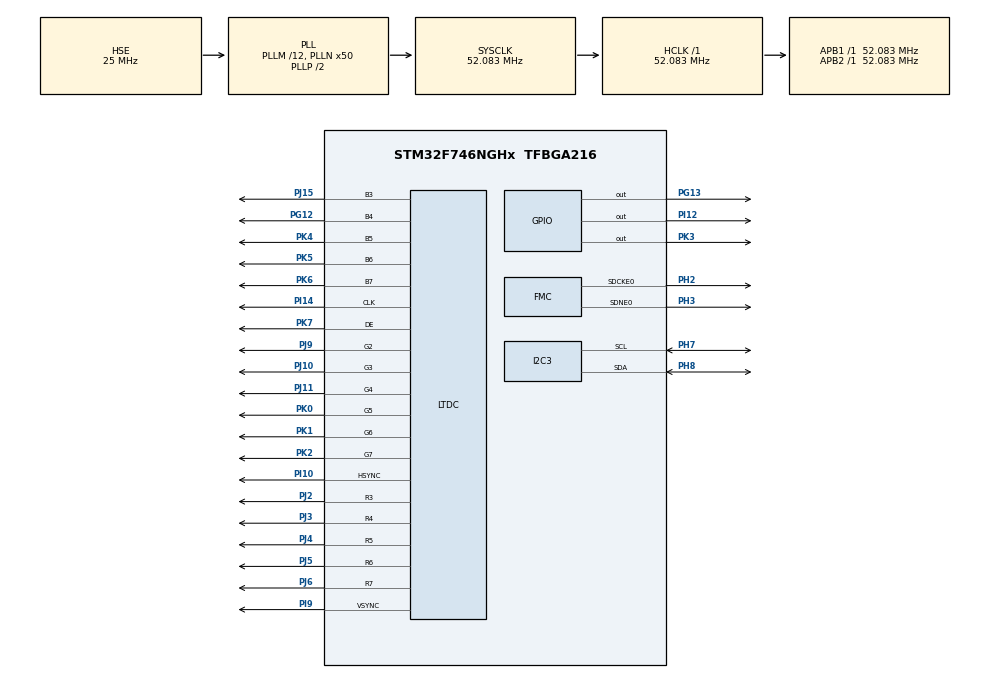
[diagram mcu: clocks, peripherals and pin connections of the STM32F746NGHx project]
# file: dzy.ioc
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GRAPHICS.BSP.number=1
GRAPHICS.Check_OTM8009A_PixelFormat-STemWin=1
GRAPHICS.DMA2D_Graphics-STemWin=0
GRAPHICS.EA_1_Apptype=Window
GRAPHICS.EA_1_executable_name-STemWin=GUIBuilder.exe
GRAPHICS.GUI_NUM_LAYERS-STemWin=1
GRAPHICS.GUI_Num_KBYTES=10
GRAPHICS.LIN_Color_Conversion_Layer0=GUICC_M565
GRAPHICS.LIN_Frame_Buffer_Depth_Layer0-STemWin=16
GRAPHICS.OPTIM_OS_use-STemWin=4
GRAPHICS.USE_Embedded_Wizard-STemWin=0
GRAPHICS.USE_STTouchGFX-STemWin=0
GRAPHICS.UseGUIBuilder=Enabled
GRAPHICS.Use_SDRAM-STemWin=SDRAM1_BANK1
GRAPHICS0.BSP.STBoard=false
GRAPHICS0.BSP.api=Unknown
GRAPHICS0.BSP.i2caddr=0
GRAPHICS0.BSP.instance=PG13
GRAPHICS0.BSP.ip=GPIO
GRAPHICS0.BSP.mode=Output
GRAPHICS0.BSP.name=LCD Reset Pin XRES
GRAPHICS0.BSP.solution=PG13
I2C3.Timing=0x00D0FFFF
LTDC.ActiveH=272
LTDC.ActiveW=480
LTDC.Alpha_L0=255
LTDC.FBStartAdress_L0=0x20010400
LTDC.HBP=43
LTDC.HFP=8
LTDC.HSync=1
LTDC.ImageHeight_L0=272
LTDC.ImageWidth_L0=480
LTDC.Layers=0
LTDC.PixelFormat_L0=LTDC_PIXEL_FORMAT_RGB565
LTDC.VBP=12
LTDC.VFP=4
LTDC.VSync=10
LTDC.WindowX1_L0=480
LTDC.WindowY1_L0=272
Mcu.Family=STM32F7
Mcu.Name=STM32F746NGHx
Mcu.Package=TFBGA216
NVIC.PriorityGroup=NVIC_PRIORITYGROUP_4
PA13.Mode=Trace_Asynchronous_SW
PA13.Signal=SYS_JTMS-SWDIO
PA14.Mode=Trace_Asynchronous_SW
PA14.Signal=SYS_JTCK-SWCLK
PB3.Mode=Trace_Asynchronous_SW
PB3.Signal=SYS_JTDO-SWO
PG12.Mode=RGB565
PG12.Signal=LTDC_B4
PG13.Signal=GPIO_Output
PH0/OSC_IN.Mode=HSE-External-Oscillator
PH0/OSC_IN.Signal=RCC_OSC_IN
PH1/OSC_OUT.Mode=HSE-External-Oscillator
PH1/OSC_OUT.Signal=RCC_OSC_OUT
PH2.Mode=SdramChipSelect1_1
PH2.Signal=FMC_SDCKE0
PH3.Mode=SdramChipSelect1_1
PH3.Signal=FMC_SDNE0
PH7.Mode=I2C
PH7.Signal=I2C3_SCL
PH8.Mode=I2C
PH8.Signal=I2C3_SDA
PI10.Mode=RGB565
PI10.Signal=LTDC_HSYNC
PI12.PinState=GPIO_PIN_SET
PI12.Signal=GPIO_Output
PI14.Mode=RGB565
PI14.Signal=LTDC_CLK
PI9.Mode=RGB565
PI9.Signal=LTDC_VSYNC
PJ10.Mode=RGB565
PJ10.Signal=LTDC_G3
PJ11.Mode=RGB565
PJ11.Signal=LTDC_G4
PJ15.Mode=RGB565
PJ15.Signal=LTDC_B3
PJ2.Mode=RGB565
PJ2.Signal=LTDC_R3
PJ3.Mode=RGB565
PJ3.Signal=LTDC_R4
PJ4.Mode=RGB565
PJ4.Signal=LTDC_R5
PJ5.Mode=RGB565
PJ5.Signal=LTDC_R6
PJ6.Mode=RGB565
PJ6.Signal=LTDC_R7
PJ9.Mode=RGB565
PJ9.Signal=LTDC_G2
PK0.Mode=RGB565
PK0.Signal=LTDC_G5
PK1.Mode=RGB565
PK1.Signal=LTDC_G6
PK2.Mode=RGB565
PK2.Signal=LTDC_G7
PK3.PinState=GPIO_PIN_SET
PK3.Signal=GPIO_Output
PK4.Mode=RGB565
PK4.Signal=LTDC_B5
PK5.Mode=RGB565
PK5.Signal=LTDC_B6
PK6.Mode=RGB565
PK6.Signal=LTDC_B7
PK7.Mode=RGB565
PK7.Signal=LTDC_DE
ProjectManager.HeapSize=0x1000
ProjectManager.StackSize=0x1000
ProjectManager.TargetToolchain=EWARM V8
RCC.AHBFreq_Value=52083333.33333333
RCC.APB1Freq_Value=52083333.33333333
RCC.APB1TimFreq_Value=52083333.33333333
RCC.APB2Freq_Value=52083333.33333333
RCC.APB2TimFreq_Value=52083333.33333333
RCC.CortexFreq_Value=52083333.33333333
RCC.HCLKFreq_Value=52083333.33333333
RCC.HSE_VALUE=25000000
RCC.HSI_VALUE=16000000
RCC.LSE_VALUE=32768
RCC.PLLM=12
RCC.PLLN=50
RCC.PLLSAIN=96
RCC.PLLSAIR=5
RCC.PLLSAIRDiv=RCC_PLLSAIDIVR_4
RCC.PLLSourceVirtual=RCC_PLLSOURCE_HSE
RCC.SYSCLKFreq_VALUE=52083333.33333333
RCC.SYSCLKSource=RCC_SYSCLKSOURCE_PLLCLK
RCC.USBFreq_Value=52083333.33333333
RCC.VCOOutputFreq_Value=104166666.66666666
RTC.Format=RTC_FORMAT_BIN
VP_CRC_VS_CRC.Mode=CRC_Activate
VP_GRAPHICS_VS-DisplayInterface-LTDC.Mode=Display Parallel Interface using LTDC
VP_GRAPHICS_VS-STemWin.Mode=STemWin
VP_RTC_VS_RTC_Activate.Mode=RTC_Enabled
VP_RTC_VS_RTC_Calendar.Mode=RTC_Calendar
board=custom

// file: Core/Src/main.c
/* USER CODE BEGIN Header */
/**
  ******************************************************************************
  * @file           : main.c
  * @brief          : Main program body
  ******************************************************************************
  * @attention
  *
  * <h2><center>&copy; Copyright (c) 2020 STMicroelectronics.
  * All rights reserved.</center></h2>
  *
  * This software component is licensed by ST under Ultimate Liberty license
  * SLA0044, the "License"; You may not use this file except in compliance with
  * the License. You may obtain a copy of the License at:
  *                             www.st.com/SLA0044
  *
  ******************************************************************************
  */
/* USER CODE END Header */

#include "main.h"

/* USER CODE BEGIN Includes */

/*2020.10.26改动说明--孙天一
STM32CubeMax：
  工程重建，配置了工程文件选项：主要包括基础配置以及RTC、FMC、I2C3和LTDC以及GRAPHICS
IAR:
  因程序走入死循环且诊断不出问题所在，重新开始工程和程序编写。

*/

#include <stdio.h>

/* USER CODE END Includes */

CRC_HandleTypeDef hcrc;

I2C_HandleTypeDef hi2c3;

RTC_HandleTypeDef hrtc;

void SystemClock_Config(void);
static void MX_GPIO_Init(void);
static void MX_I2C3_Init(void);
static void MX_RTC_Init(void);
static void MX_CRC_Init(void);
extern void GRAPHICS_HW_Init(void);
extern void GRAPHICS_Init(void);
extern void GRAPHICS_MainTask(void);
/* USER CODE BEGIN PFP */
  RTC_TimeTypeDef sTime;//定义时间结构体
  RTC_DateTypeDef sDate;

/* USER CODE END PFP */

/* USER CODE BEGIN 0 */
void checkTouch(void)
{
    uint8_t buf[6];
    HAL_I2C_Mem_Read(&hi2c3, 0x70, 0x02, 1, buf, 1, 1000);
    //printf("Touch: %d point\n", buf[0]);

    if(buf[0] > 0 && buf[0] < 6)
    {
        HAL_I2C_Mem_Read(&hi2c3, 0x70, 0x03, 1, buf, 4, 1000);
        //printf("y: %d\n", (buf[0]<<8 | buf[1]) & 0x0fff);
        //printf("x: %d\n", (buf[2]<<8 | buf[3]) & 0x0fff);
        GUI_TOUCH_StoreState((buf[2]<<8 | buf[3]) & 0x0fff, (buf[0]<<8 | buf[1]) & 0x0fff);
    }
    else
    {
        GUI_TOUCH_StoreState(-1, -1);
    }
}
/* USER CODE END 0 */

int main(void)
{

  /* MCU Configuration--------------------------------------------------------*/

  /* Reset of all peripherals, Initializes the Flash interface and the Systick. */
  HAL_Init();

  /* Configure the system clock */
  SystemClock_Config();

  /* Initialize all configured peripherals */
  MX_GPIO_Init();
  MX_I2C3_Init();
  MX_RTC_Init();
  MX_CRC_Init();
  /* USER CODE BEGIN 2 */

//    while(1)
//{
//      GUI_Delay(900);
//      HAL_RTC_GetTime(&hrtc, &sTime, RTC_FORMAT_BIN);//得到时间和时期
//      HAL_RTC_GetDate(&hrtc, &sDate, RTC_FORMAT_BIN);
//      HAL_RTCEx_BKUPWrite(&hrtc,RTC_BKP_DR0,0x32F2);
//      printf("%02d/%02d/%02d\r\n",2000 + sDate.Year, sDate.Month, sDate.Date);
//      printf("%02d:%02d:%02d\r\n",sTime.Hours, sTime.Minutes, sTime.Seconds);
//}

  /* USER CODE END 2 */

/* Initialise the graphical hardware */
  GRAPHICS_HW_Init();

  /* Initialise the graphical stack engine */
  GRAPHICS_Init();

  /* Graphic application */
  GRAPHICS_MainTask();

  /* Infinite loop */
  for(;;);
}

void SystemClock_Config(void)
{
  RCC_OscInitTypeDef RCC_OscInitStruct = {0};
  RCC_ClkInitTypeDef RCC_ClkInitStruct = {0};
  RCC_PeriphCLKInitTypeDef PeriphClkInitStruct = {0};

  /** Configure the main internal regulator output voltage
  */
  __HAL_RCC_PWR_CLK_ENABLE();
  __HAL_PWR_VOLTAGESCALING_CONFIG(PWR_REGULATOR_VOLTAGE_SCALE3);
  /** Initializes the CPU, AHB and APB busses clocks
  */
  RCC_OscInitStruct.OscillatorType = RCC_OSCILLATORTYPE_LSI|RCC_OSCILLATORTYPE_HSE;
  RCC_OscInitStruct.HSEState = RCC_HSE_ON;
  RCC_OscInitStruct.LSIState = RCC_LSI_ON;
  RCC_OscInitStruct.PLL.PLLState = RCC_PLL_ON;
  RCC_OscInitStruct.PLL.PLLSource = RCC_PLLSOURCE_HSE;
  RCC_OscInitStruct.PLL.PLLM = 12;
  RCC_OscInitStruct.PLL.PLLN = 50;
  RCC_OscInitStruct.PLL.PLLP = RCC_PLLP_DIV2;
  RCC_OscInitStruct.PLL.PLLQ = 2;
  if (HAL_RCC_OscConfig(&RCC_OscInitStruct) != HAL_OK)
  {
    Error_Handler();
  }
  /** Activate the Over-Drive mode
  */
  if (HAL_PWREx_EnableOverDrive() != HAL_OK)
  {
    Error_Handler();
  }
  /** Initializes the CPU, AHB and APB busses clocks
  */
  RCC_ClkInitStruct.ClockType = RCC_CLOCKTYPE_HCLK|RCC_CLOCKTYPE_SYSCLK
                              |RCC_CLOCKTYPE_PCLK1|RCC_CLOCKTYPE_PCLK2;
  RCC_ClkInitStruct.SYSCLKSource = RCC_SYSCLKSOURCE_PLLCLK;
  RCC_ClkInitStruct.AHBCLKDivider = RCC_SYSCLK_DIV1;
  RCC_ClkInitStruct.APB1CLKDivider = RCC_HCLK_DIV1;
  RCC_ClkInitStruct.APB2CLKDivider = RCC_HCLK_DIV1;

  if (HAL_RCC_ClockConfig(&RCC_ClkInitStruct, FLASH_LATENCY_1) != HAL_OK)
  {
    Error_Handler();
  }
  PeriphClkInitStruct.PeriphClockSelection = RCC_PERIPHCLK_LTDC|RCC_PERIPHCLK_RTC
                              |RCC_PERIPHCLK_I2C3;
  PeriphClkInitStruct.PLLSAI.PLLSAIN = 96;
  PeriphClkInitStruct.PLLSAI.PLLSAIR = 5;
  PeriphClkInitStruct.PLLSAI.PLLSAIQ = 2;
  PeriphClkInitStruct.PLLSAI.PLLSAIP = RCC_PLLSAIP_DIV2;
  PeriphClkInitStruct.PLLSAIDivQ = 1;
  PeriphClkInitStruct.PLLSAIDivR = RCC_PLLSAIDIVR_4;
  PeriphClkInitStruct.RTCClockSelection = RCC_RTCCLKSOURCE_LSI;
  PeriphClkInitStruct.I2c3ClockSelection = RCC_I2C3CLKSOURCE_PCLK1;
  if (HAL_RCCEx_PeriphCLKConfig(&PeriphClkInitStruct) != HAL_OK)
  {
    Error_Handler();
  }
}

static void MX_CRC_Init(void)
{

  hcrc.Instance = CRC;
  hcrc.Init.DefaultPolynomialUse = DEFAULT_POLYNOMIAL_ENABLE;
  hcrc.Init.DefaultInitValueUse = DEFAULT_INIT_VALUE_ENABLE;
  hcrc.Init.InputDataInversionMode = CRC_INPUTDATA_INVERSION_NONE;
  hcrc.Init.OutputDataInversionMode = CRC_OUTPUTDATA_INVERSION_DISABLE;
  hcrc.InputDataFormat = CRC_INPUTDATA_FORMAT_BYTES;
  if (HAL_CRC_Init(&hcrc) != HAL_OK)
  {
    Error_Handler();
  }

}

static void MX_I2C3_Init(void)
{

  hi2c3.Instance = I2C3;
  hi2c3.Init.Timing = 0x00D0FFFF;
  hi2c3.Init.OwnAddress1 = 0;
  hi2c3.Init.AddressingMode = I2C_ADDRESSINGMODE_7BIT;
  hi2c3.Init.DualAddressMode = I2C_DUALADDRESS_DISABLE;
  hi2c3.Init.OwnAddress2 = 0;
  hi2c3.Init.OwnAddress2Masks = I2C_OA2_NOMASK;
  hi2c3.Init.GeneralCallMode = I2C_GENERALCALL_DISABLE;
  hi2c3.Init.NoStretchMode = I2C_NOSTRETCH_DISABLE;
  if (HAL_I2C_Init(&hi2c3) != HAL_OK)
  {
    Error_Handler();
  }
  /** Configure Analogue filter
  */
  if (HAL_I2CEx_ConfigAnalogFilter(&hi2c3, I2C_ANALOGFILTER_ENABLE) != HAL_OK)
  {
    Error_Handler();
  }
  /** Configure Digital filter
  */
  if (HAL_I2CEx_ConfigDigitalFilter(&hi2c3, 0) != HAL_OK)
  {
    Error_Handler();
  }

}

static void MX_RTC_Init(void)
{

  /* USER CODE BEGIN RTC_Init 0 */
 //RTC参数设置

  /* USER CODE END RTC_Init 0 */

  RTC_TimeTypeDef sTime = {0};
  RTC_DateTypeDef sDate = {0};

  /** Initialize RTC Only
  */
  hrtc.Instance = RTC;
  hrtc.Init.HourFormat = RTC_HOURFORMAT_24;
  hrtc.Init.AsynchPrediv = 127;
  hrtc.Init.SynchPrediv = 255;
  hrtc.Init.OutPut = RTC_OUTPUT_DISABLE;
  hrtc.Init.OutPutPolarity = RTC_OUTPUT_POLARITY_HIGH;
  hrtc.Init.OutPutType = RTC_OUTPUT_TYPE_OPENDRAIN;
  if (HAL_RTC_Init(&hrtc) != HAL_OK)
  {
    Error_Handler();
  }

  /* USER CODE BEGIN Check_RTC_BKUP */

//  hrtc.Instance = RTC;
//  hrtc.Init.AsynchPrediv = RTC_AUTO_1_SECOND;
//  hrtc.Init.OutPut = RTC_OUTPUTSOURCE_NONE;
//  if (HAL_RTC_Init(&hrtc) != HAL_OK)
//  {
//    Error_Handler();
//  }

  /* USER CODE END Check_RTC_BKUP */

  /** Initialize RTC and set the Time and Date
  */
  sTime.Hours = 0;
  sTime.Minutes = 0;
  sTime.Seconds = 0;
  sTime.DayLightSaving = RTC_DAYLIGHTSAVING_NONE;
  sTime.StoreOperation = RTC_STOREOPERATION_RESET;
  if (HAL_RTC_SetTime(&hrtc, &sTime, RTC_FORMAT_BIN) != HAL_OK)
  {
    Error_Handler();
  }
  sDate.WeekDay = RTC_WEEKDAY_MONDAY;
  sDate.Month = RTC_MONTH_JANUARY;
  sDate.Date = 1;
  sDate.Year = 0;
  if (HAL_RTC_SetDate(&hrtc, &sDate, RTC_FORMAT_BIN) != HAL_OK)
  {
    Error_Handler();
  }
  /* USER CODE BEGIN RTC_Init 2 */

  //设置RTC定时时间1s
  if(HAL_RTCEx_SetWakeUpTimer_IT(&hrtc,1,RTC_WAKEUPCLOCK_CK_SPRE_16BITS)!=HAL_OK)
  {
    Error_Handler();
  }
  /* USER CODE END RTC_Init 2 */

}

static void MX_GPIO_Init(void)
{
  GPIO_InitTypeDef GPIO_InitStruct = {0};

  /* GPIO Ports Clock Enable */
  __HAL_RCC_GPIOB_CLK_ENABLE();
  __HAL_RCC_GPIOA_CLK_ENABLE();
  __HAL_RCC_GPIOG_CLK_ENABLE();
  __HAL_RCC_GPIOK_CLK_ENABLE();
  __HAL_RCC_GPIOI_CLK_ENABLE();
  __HAL_RCC_GPIOJ_CLK_ENABLE();
  __HAL_RCC_GPIOH_CLK_ENABLE();

  /*Configure GPIO pin Output Level */
  HAL_GPIO_WritePin(GPIOG, GPIO_PIN_13, GPIO_PIN_RESET);

  /*Configure GPIO pin Output Level */
  HAL_GPIO_WritePin(GPIOK, GPIO_PIN_3, GPIO_PIN_SET);

  /*Configure GPIO pin Output Level */
  HAL_GPIO_WritePin(GPIOI, GPIO_PIN_12, GPIO_PIN_SET);

  /*Configure GPIO pin : PG13 */
  GPIO_InitStruct.Pin = GPIO_PIN_13;
  GPIO_InitStruct.Mode = GPIO_MODE_OUTPUT_PP;
  GPIO_InitStruct.Pull = GPIO_NOPULL;
  GPIO_InitStruct.Speed = GPIO_SPEED_FREQ_LOW;
  HAL_GPIO_Init(GPIOG, &GPIO_InitStruct);

  /*Configure GPIO pin : PK3 */
  GPIO_InitStruct.Pin = GPIO_PIN_3;
  GPIO_InitStruct.Mode = GPIO_MODE_OUTPUT_PP;
  GPIO_InitStruct.Pull = GPIO_NOPULL;
  GPIO_InitStruct.Speed = GPIO_SPEED_FREQ_LOW;
  HAL_GPIO_Init(GPIOK, &GPIO_InitStruct);

  /*Configure GPIO pin : PI12 */
  GPIO_InitStruct.Pin = GPIO_PIN_12;
  GPIO_InitStruct.Mode = GPIO_MODE_OUTPUT_PP;
  GPIO_InitStruct.Pull = GPIO_NOPULL;
  GPIO_InitStruct.Speed = GPIO_SPEED_FREQ_LOW;
  HAL_GPIO_Init(GPIOI, &GPIO_InitStruct);

}

void Error_Handler(void)
{
}

/************************ (C) COPYRIGHT STMicroelectronics *****END OF FILE****/
